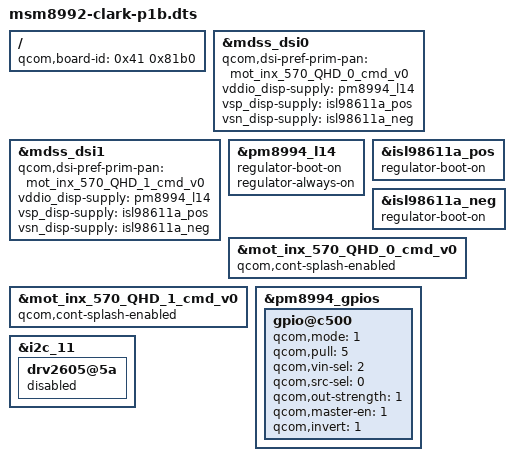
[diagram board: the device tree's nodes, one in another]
/* Copyright (c) 2015, Motorola Mobility LLC. All rights reserved.
 *
 * This program is free software; you can redistribute it and/or modify
 * it under the terms of the GNU General Public License version 2 and
 * only version 2 as published by the Free Software Foundation.
 *
 * This program is distributed in the hope that it will be useful,
 * but WITHOUT ANY WARRANTY; without even the implied warranty of
 * MERCHANTABILITY or FITNESS FOR A PARTICULAR PURPOSE.  See the
 * GNU General Public License for more details.
 */


/dts-v1/;

#include "msm8992-clark.dtsi"
#include "dsi-panel-mot-inx-570-QHD-cmd.dtsi"

/ {
	qcom,board-id = <0x41 0x81b0>;
};

&mdss_dsi0 {
	qcom,dsi-pref-prim-pan = <&mot_inx_570_QHD_0_cmd_v0>;
	vddio_disp-supply = <&pm8994_l14>;
	vsp_disp-supply = <&isl98611a_pos>;
	vsn_disp-supply = <&isl98611a_neg>;

	#include"dsi-panel-mot-inx-570-QHD-supplies.dtsi"
};

&mdss_dsi1 {
	qcom,dsi-pref-prim-pan = <&mot_inx_570_QHD_1_cmd_v0>;
	vddio_disp-supply = <&pm8994_l14>;
	vsp_disp-supply = <&isl98611a_pos>;
	vsn_disp-supply = <&isl98611a_neg>;

	#include"dsi-panel-mot-inx-570-QHD-supplies.dtsi"
};

&pm8994_l14 {
	regulator-boot-on;
	regulator-always-on;
};

&isl98611a_pos {
	regulator-boot-on;
};

&isl98611a_neg {
	regulator-boot-on;
};

&mot_inx_570_QHD_0_cmd_v0 {
	qcom,cont-splash-enabled;
};

&mot_inx_570_QHD_1_cmd_v0 {
	qcom,cont-splash-enabled;
};

&pm8994_gpios {
	gpio@c500 { /* GPIO 6 - DISP_V3_EN */
		status = "okay";
		qcom,mode = <1>; /* Output */
		qcom,pull = <5>; /* None */
		qcom,vin-sel = <2>;
		qcom,src-sel = <0>; /* FUNC_CONSTANT */
		qcom,out-strength = <1>;
		qcom,master-en = <1>;
		qcom,invert = <1>; /* Invert default 0 to get 1 */
	};
};

&i2c_11 {
	drv2605@5a {
		status = "disabled";
	};
};
